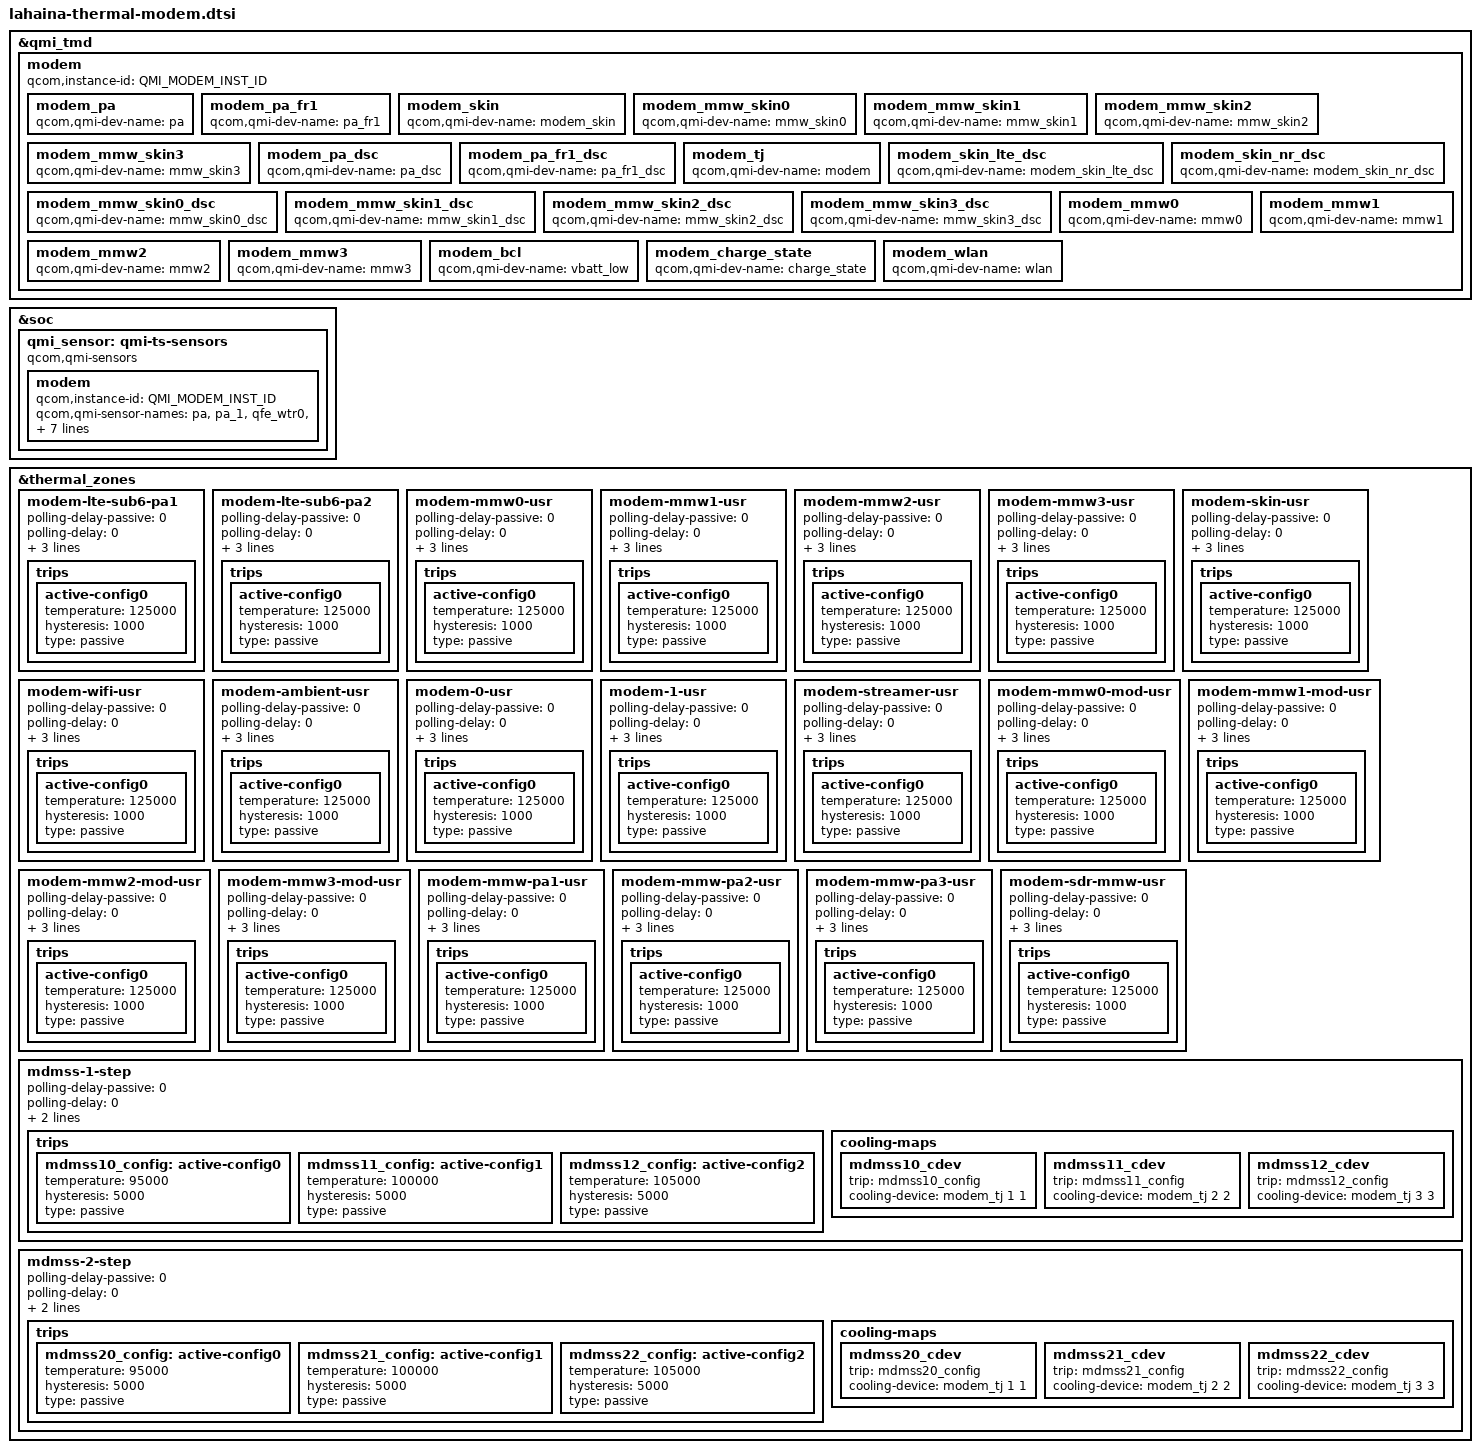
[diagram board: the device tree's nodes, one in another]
&qmi_tmd {
	modem {
		qcom,instance-id = <QMI_MODEM_INST_ID>;

		modem_pa: modem_pa {
			qcom,qmi-dev-name = "pa";
			#cooling-cells = <2>;
		};

		modem_pa_fr1: modem_pa_fr1 {
			qcom,qmi-dev-name = "pa_fr1";
			#cooling-cells = <2>;
		};

		modem_skin: modem_skin {
			qcom,qmi-dev-name = "modem_skin";
			#cooling-cells = <2>;
		};

		modem_mmw_skin0: modem_mmw_skin0 {
			qcom,qmi-dev-name = "mmw_skin0";
			#cooling-cells = <2>;
		};

		modem_mmw_skin1: modem_mmw_skin1 {
			qcom,qmi-dev-name = "mmw_skin1";
			#cooling-cells = <2>;
		};

		modem_mmw_skin2: modem_mmw_skin2 {
			qcom,qmi-dev-name = "mmw_skin2";
			#cooling-cells = <2>;
		};

		modem_mmw_skin3: modem_mmw_skin3 {
			qcom,qmi-dev-name = "mmw_skin3";
			#cooling-cells = <2>;
		};

		modem_pa_dsc: modem_pa_dsc {
			qcom,qmi-dev-name = "pa_dsc";
			#cooling-cells = <2>;
		};

		modem_pa_fr1_dsc: modem_pa_fr1_dsc {
			qcom,qmi-dev-name = "pa_fr1_dsc";
			#cooling-cells = <2>;
		};

		modem_tj: modem_tj {
			qcom,qmi-dev-name = "modem";
			#cooling-cells = <2>;
		};

		modem_skin_lte_dsc: modem_skin_lte_dsc {
			qcom,qmi-dev-name = "modem_skin_lte_dsc";
			#cooling-cells = <2>;
		};

		modem_skin_nr_dsc: modem_skin_nr_dsc {
			qcom,qmi-dev-name = "modem_skin_nr_dsc";
			#cooling-cells = <2>;
		};

		modem_mmw_skin0_dsc: modem_mmw_skin0_dsc {
			qcom,qmi-dev-name = "mmw_skin0_dsc";
			#cooling-cells = <2>;
		};

		modem_mmw_skin1_dsc: modem_mmw_skin1_dsc {
			qcom,qmi-dev-name = "mmw_skin1_dsc";
			#cooling-cells = <2>;
		};

		modem_mmw_skin2_dsc: modem_mmw_skin2_dsc {
			qcom,qmi-dev-name = "mmw_skin2_dsc";
			#cooling-cells = <2>;
		};

		modem_mmw_skin3_dsc: modem_mmw_skin3_dsc {
			qcom,qmi-dev-name = "mmw_skin3_dsc";
			#cooling-cells = <2>;
		};

		modem_mmw0: modem_mmw0 {
			qcom,qmi-dev-name = "mmw0";
			#cooling-cells = <2>;
		};

		modem_mmw1: modem_mmw1 {
			qcom,qmi-dev-name = "mmw1";
			#cooling-cells = <2>;
		};

		modem_mmw2: modem_mmw2 {
			qcom,qmi-dev-name = "mmw2";
			#cooling-cells = <2>;
		};

		modem_mmw3: modem_mmw3 {
			qcom,qmi-dev-name = "mmw3";
			#cooling-cells = <2>;
		};

		modem_bcl: modem_bcl {
			qcom,qmi-dev-name = "vbatt_low";
			#cooling-cells = <2>;
		};

		modem_charge_state: modem_charge_state {
			qcom,qmi-dev-name = "charge_state";
			#cooling-cells = <2>;
		};

		modem_wlan: modem_wlan {
			qcom,qmi-dev-name = "wlan";
			#cooling-cells = <2>;
		};
	};
};

&soc {
	qmi_sensor: qmi-ts-sensors {
		compatible = "qcom,qmi-sensors";
		#thermal-sensor-cells = <1>;

		modem {
			qcom,instance-id = <QMI_MODEM_INST_ID>;
			qcom,qmi-sensor-names = "pa",
						"pa_1",
						"qfe_wtr0",
						"modem_tsens",
						"qfe_mmw0",
						"qfe_mmw1",
						"qfe_mmw2",
						"qfe_mmw3",
						"xo_therm",
						"qfe_mmw_streamer0",
						"qfe_mmw0_mod",
						"qfe_mmw1_mod",
						"qfe_mmw2_mod",
						"qfe_mmw3_mod",
						"qfe_ret_pa0",
						"qfe_wtr_pa0",
						"qfe_wtr_pa1",
						"qfe_wtr_pa2",
						"qfe_wtr_pa3",
						"sys_therm1",
						"sys_therm2",
						"modem_tsens1",
						"mmw_pa1",
						"mmw_pa2",
						"mmw_pa3",
						"sdr_mmw_therm";
		};
	};
};

&thermal_zones {
	modem-lte-sub6-pa1 {
		polling-delay-passive = <0>;
		polling-delay = <0>;
		thermal-governor = "user_space";
		thermal-sensors = <&qmi_sensor
				(QMI_MODEM_INST_ID+QMI_PA)>;
		trips {
			active-config0 {
				temperature = <125000>;
				hysteresis = <1000>;
				type = "passive";
			};
		};
	};

	modem-lte-sub6-pa2 {
		polling-delay-passive = <0>;
		polling-delay = <0>;
		thermal-governor = "user_space";
		thermal-sensors = <&qmi_sensor
				(QMI_MODEM_INST_ID+QMI_PA_1)>;
		trips {
			active-config0 {
				temperature = <125000>;
				hysteresis = <1000>;
				type = "passive";
			};
		};
	};

	modem-mmw0-usr {
		polling-delay-passive = <0>;
		polling-delay = <0>;
		thermal-governor = "user_space";
		thermal-sensors = <&qmi_sensor
				(QMI_MODEM_INST_ID+QMI_QFE_MMW_0)>;
		trips {
			active-config0 {
				temperature = <125000>;
				hysteresis = <1000>;
				type = "passive";
			};
		};
	};

	modem-mmw1-usr {
		polling-delay-passive = <0>;
		polling-delay = <0>;
		thermal-governor = "user_space";
		thermal-sensors = <&qmi_sensor
				(QMI_MODEM_INST_ID+QMI_QFE_MMW_1)>;
		trips {
			active-config0 {
				temperature = <125000>;
				hysteresis = <1000>;
				type = "passive";
			};
		};
	};

	modem-mmw2-usr {
		polling-delay-passive = <0>;
		polling-delay = <0>;
		thermal-governor = "user_space";
		thermal-sensors = <&qmi_sensor
				(QMI_MODEM_INST_ID+QMI_QFE_MMW_2)>;
		trips {
			active-config0 {
				temperature = <125000>;
				hysteresis = <1000>;
				type = "passive";
			};
		};
	};

	modem-mmw3-usr {
		polling-delay-passive = <0>;
		polling-delay = <0>;
		thermal-governor = "user_space";
		thermal-sensors = <&qmi_sensor
				(QMI_MODEM_INST_ID+QMI_QFE_MMW_3)>;
		trips {
			active-config0 {
				temperature = <125000>;
				hysteresis = <1000>;
				type = "passive";
			};
		};
	};

	modem-skin-usr {
		polling-delay-passive = <0>;
		polling-delay = <0>;
		thermal-governor = "user_space";
		thermal-sensors = <&qmi_sensor
				(QMI_MODEM_INST_ID+QMI_XO_THERM)>;
		trips {
			active-config0 {
				temperature = <125000>;
				hysteresis = <1000>;
				type = "passive";
			};
		};
	};

	modem-wifi-usr {
		polling-delay-passive = <0>;
		polling-delay = <0>;
		thermal-governor = "user_space";
		thermal-sensors = <&qmi_sensor
				(QMI_MODEM_INST_ID+QMI_SYS_THERM_1)>;
		trips {
			active-config0 {
				temperature = <125000>;
				hysteresis = <1000>;
				type = "passive";
			};
		};
	};

	modem-ambient-usr {
		polling-delay-passive = <0>;
		polling-delay = <0>;
		thermal-governor = "user_space";
		thermal-sensors = <&qmi_sensor
				(QMI_MODEM_INST_ID+QMI_SYS_THERM_2)>;
		trips {
			active-config0 {
				temperature = <125000>;
				hysteresis = <1000>;
				type = "passive";
			};
		};
	};

	modem-0-usr {
		polling-delay-passive = <0>;
		polling-delay = <0>;
		thermal-governor = "user_space";
		thermal-sensors = <&qmi_sensor
				(QMI_MODEM_INST_ID+QMI_MODEM_TSENS)>;
		trips {
			active-config0 {
				temperature = <125000>;
				hysteresis = <1000>;
				type = "passive";
			};
		};
	};

	modem-1-usr {
		polling-delay-passive = <0>;
		polling-delay = <0>;
		thermal-governor = "user_space";
		thermal-sensors = <&qmi_sensor
				(QMI_MODEM_INST_ID+QMI_MODEM_TSENS_1)>;
		trips {
			active-config0 {
				temperature = <125000>;
				hysteresis = <1000>;
				type = "passive";
			};
		};
	};

	modem-streamer-usr {
		polling-delay-passive = <0>;
		polling-delay = <0>;
		thermal-governor = "user_space";
		thermal-sensors = <&qmi_sensor
				(QMI_MODEM_INST_ID+QMI_QFE_MMW_STREAMER_0)>;
		trips {
			active-config0 {
				temperature = <125000>;
				hysteresis = <1000>;
				type = "passive";
			};
		};
	};

	modem-mmw0-mod-usr {
		polling-delay-passive = <0>;
		polling-delay = <0>;
		thermal-governor = "user_space";
		thermal-sensors = <&qmi_sensor
				(QMI_MODEM_INST_ID+QMI_QFE_MMW_0_MOD)>;
		trips {
			active-config0 {
				temperature = <125000>;
				hysteresis = <1000>;
				type = "passive";
			};
		};
	};

	modem-mmw1-mod-usr {
		polling-delay-passive = <0>;
		polling-delay = <0>;
		thermal-governor = "user_space";
		thermal-sensors = <&qmi_sensor
				(QMI_MODEM_INST_ID+QMI_QFE_MMW_1_MOD)>;
		trips {
			active-config0 {
				temperature = <125000>;
				hysteresis = <1000>;
				type = "passive";
			};
		};
	};

	modem-mmw2-mod-usr {
		polling-delay-passive = <0>;
		polling-delay = <0>;
		thermal-governor = "user_space";
		thermal-sensors = <&qmi_sensor
				(QMI_MODEM_INST_ID+QMI_QFE_MMW_2_MOD)>;
		trips {
			active-config0 {
				temperature = <125000>;
				hysteresis = <1000>;
				type = "passive";
			};
		};
	};

	modem-mmw3-mod-usr {
		polling-delay-passive = <0>;
		polling-delay = <0>;
		thermal-governor = "user_space";
		thermal-sensors = <&qmi_sensor
				(QMI_MODEM_INST_ID+QMI_QFE_MMW_3_MOD)>;
		trips {
			active-config0 {
				temperature = <125000>;
				hysteresis = <1000>;
				type = "passive";
			};
		};
	};

	modem-mmw-pa1-usr {
		polling-delay-passive = <0>;
		polling-delay = <0>;
		thermal-governor = "user_space";
		thermal-sensors = <&qmi_sensor
				(QMI_MODEM_INST_ID+QMI_MMW_PA1)>;
		trips {
			active-config0 {
				temperature = <125000>;
				hysteresis = <1000>;
				type = "passive";
			};
		};
	};

	modem-mmw-pa2-usr {
		polling-delay-passive = <0>;
		polling-delay = <0>;
		thermal-governor = "user_space";
		thermal-sensors = <&qmi_sensor
				(QMI_MODEM_INST_ID+QMI_MMW_PA2)>;
		trips {
			active-config0 {
				temperature = <125000>;
				hysteresis = <1000>;
				type = "passive";
			};
		};
	};

	modem-mmw-pa3-usr {
		polling-delay-passive = <0>;
		polling-delay = <0>;
		thermal-governor = "user_space";
		thermal-sensors = <&qmi_sensor
				(QMI_MODEM_INST_ID+QMI_MMW_PA3)>;
		trips {
			active-config0 {
				temperature = <125000>;
				hysteresis = <1000>;
				type = "passive";
			};
		};
	};

	modem-sdr-mmw-usr {
		polling-delay-passive = <0>;
		polling-delay = <0>;
		thermal-governor = "user_space";
		thermal-sensors = <&qmi_sensor
				(QMI_MODEM_INST_ID+QMI_SDR_MMW)>;
		trips {
			active-config0 {
				temperature = <125000>;
				hysteresis = <1000>;
				type = "passive";
			};
		};
	};

	mdmss-1-step {
		polling-delay-passive = <0>;
		polling-delay = <0>;
		thermal-governor = "step_wise";
		thermal-sensors = <&tsens1 9>;
		trips {
			mdmss10_config: active-config0 {
				temperature = <95000>;
				hysteresis = <5000>;
				type = "passive";
			};

			mdmss11_config: active-config1 {
				temperature = <100000>;
				hysteresis = <5000>;
				type = "passive";
			};

			mdmss12_config: active-config2 {
				temperature = <105000>;
				hysteresis = <5000>;
				type = "passive";
			};
		};

		cooling-maps {
			mdmss10_cdev {
				trip = <&mdmss10_config>;
				cooling-device = <&modem_tj 1 1>;
			};

			mdmss11_cdev {
				trip = <&mdmss11_config>;
				cooling-device = <&modem_tj 2 2>;
			};

			mdmss12_cdev {
				trip = <&mdmss12_config>;
				cooling-device = <&modem_tj 3 3>;
			};
		};
	};

	mdmss-2-step {
		polling-delay-passive = <0>;
		polling-delay = <0>;
		thermal-governor = "step_wise";
		thermal-sensors = <&tsens1 10>;
		trips {
			mdmss20_config: active-config0 {
				temperature = <95000>;
				hysteresis = <5000>;
				type = "passive";
			};

			mdmss21_config: active-config1 {
				temperature = <100000>;
				hysteresis = <5000>;
				type = "passive";
			};

			mdmss22_config: active-config2 {
				temperature = <105000>;
				hysteresis = <5000>;
				type = "passive";
			};
		};

		cooling-maps {
			mdmss20_cdev {
				trip = <&mdmss20_config>;
				cooling-device = <&modem_tj 1 1>;
			};

			mdmss21_cdev {
				trip = <&mdmss21_config>;
				cooling-device = <&modem_tj 2 2>;
			};

			mdmss22_cdev {
				trip = <&mdmss22_config>;
				cooling-device = <&modem_tj 3 3>;
			};
		};
	};
};
